# AC7842x register map
Vendor: AutoChips; Series: AC78; File version: 1.0
CPU: CM4 r0p1, little endian, MPU, FPU, VTOR, 4 interrupt priority bits
Registers are 32-bit, read-write, reset 0x0 unless marked. A register's access mark holds for its fields unless they carry their own. Offsets are from the block's base; [hi:lo] are bit positions; {n}, {i} and the like mark numbered series; 'fields as' and 'values as' point back to an identical list.

## SMU — Safety Management Uint
Base 0x40089000
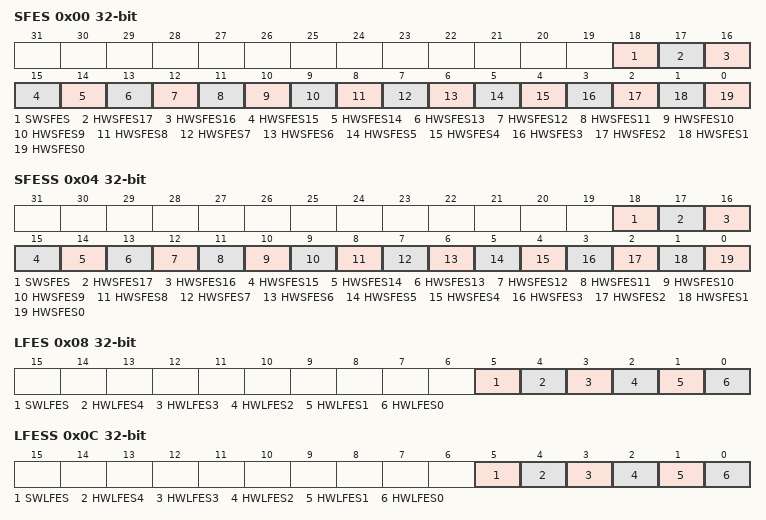
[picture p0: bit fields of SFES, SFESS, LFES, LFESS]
0x00 SFES — Single Point Fault Error Status Register
  [18] SWSFES — Software single fault error detected
  [17] HWSFES17 — FlexRAM ECC error detected
  [16] HWSFES16 — CPU lock up
  [15] HWSFES15 — Cache parity error
  [14] HWSFES14 — Low voltage detection of FLHLDO
  [13] HWSFES13 — Low voltage detection of DIGLDO
  [12] HWSFES12 — Low voltage detection of DVDD
  [11] HWSFES11 — WDG timeout
  [10] HWSFES10 — The number of trigger generated in a counting period is not equal to the set number detected
  [9] HWSFES9 — The number of trigger generated in a counting period is not equal to the set number detected
  [8] HWSFES8 — Flash ECC error detected
  [7] HWSFES7 — DMA parity error detected
  [6] HWSFES6 — End-to-end parity error detected
  [5] HWSFES5 — ECC 2 bits error detected
  [4] HWSFES4 — ECC 1 bit error detected
  [3] HWSFES3 — VHSI clock loss detected in digital module
  [2] HWSFES2 — HSE clock loss detected in digital module
  [1] HWSFES1 — PLL clock loss detected in digital module
  [0] HWSFES0 — PLL clock unlock detected in analog module
0x04 SFESS — Single Point Fault Error Status Shadow Register
  fields as SFES
0x08 LFES — Latent Fault Error Status Register
  [5] SWLFES — Software latent fault error
  [4] HWLFES4 — Memory build-in self-test error
  [3] HWLFES3 — Automatic build-in self-test error
  [2] HWLFES2 — Flash ECC error detected
  [1] HWLFES1 — ECC 1 bit error detected when EIM
  [0] HWLFES0 — ECC 2 bits error detected when EIM
0x0C LFESS — Latent Fault Error Status Shadow Register
  fields as LFES
0x10 LKSEQ0 — Lock Sequence for Single Point Fault Path
  [7:0] LKSEQ0
0x14 LKSEQ1 — Lock Sequence for Latent Fault Path
  [7:0] LKSEQ1
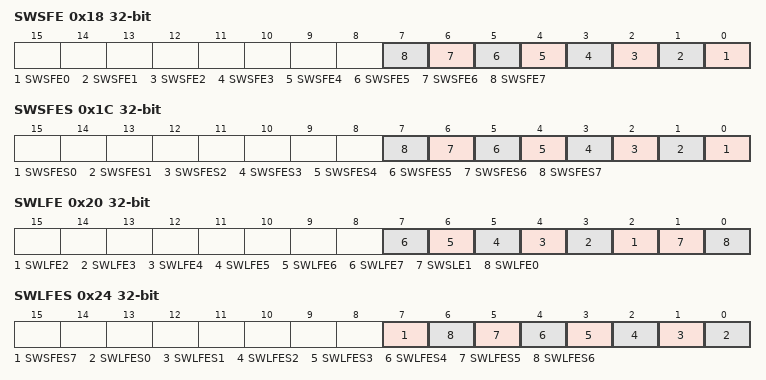
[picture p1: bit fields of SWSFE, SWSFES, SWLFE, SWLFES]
0x18 SWSFE — Software Single Point Fault Enable Register
  [n] SWSFE{n} (n=0..7) — Software Single Point Fault Enable {n}
0x1C SWSFES — Software Single Point Fault Enable Shadow Register
  [n] SWSFES{n} (n=0..7) — Software Single Point Fault Enable Shadow {n}
0x20 SWLFE — Software Latent Fault Enable Register
  [n] SWLFE{n} (n=2..7) — Software Latent Fault Enable {n}
  [1] SWSLE1 — Software Latent Fault Enable 1
  [0] SWLFE0 — Software Latent Fault Enable 0
0x24 SWLFES — Software Latent Fault Enable Shadow Register
  [7] SWSFES7 — Software Latent Fault Enable Shadow 7
  [n] SWLFES{n} (n=0..6) — Software Latent Fault Enable Shadow {n}
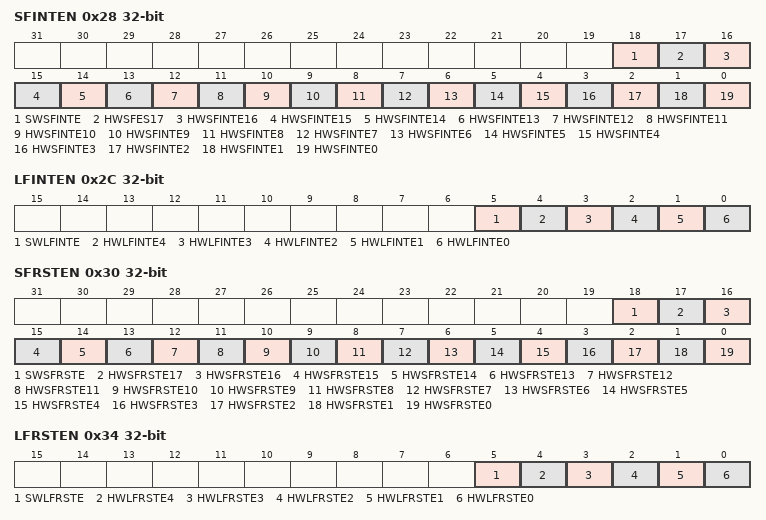
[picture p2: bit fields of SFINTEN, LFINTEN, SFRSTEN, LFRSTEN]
0x28 SFINTEN — Single Point Fault Interrupt Enable Register
  [18] SWSFINTE — Software single point interrupt enable
  [17] HWSFES17 — FlexRAM ECC error detected interrupt enable
  [16] HWSFINTE16 — CPU lock up interrupt enable
  [15] HWSFINTE15 — PFlash Cache ECC error interrupt enable
  [14] HWSFINTE14 — Low voltage detection of FLHLDO interrupt enable
  [13] HWSFINTE13 — Low voltage detection of DIGLDO interrupt enable
  [12] HWSFINTE12 — Low voltage detection of DVDD interrupt enable
  [11] HWSFINTE11 — WDG timeout interrupt enable
  [10] HWSFINTE10 — PDT0 error interrupt enable
  [9] HWSFINTE9 — PDT1 error interrupt enable
  [8] HWSFINTE8 — Flash ECC error interrupt enable
  [7] HWSFINTE7 — DMA ECC error interrupt enable
  [6] HWSFINTE6 — End-to-end ECC error interrupt enable
  [5] HWSFINTE5 — SRAM ECC 2 bits error interrupt enable
  [4] HWSFINTE4 — SRAM ECC 1 bit error interrupt enable
  [3] HWSFINTE3 — VHSI clock loss interrupt enable
  [2] HWSFINTE2 — HSE clock loss interrupt enable
  [1] HWSFINTE1 — PLL clock loss interrupt enable
  [0] HWSFINTE0 — PLL clock unlock interrupt enable
0x2C LFINTEN — Latent Fault Interrupt Enable Register
  [5] SWLFINTE — Software latent fault interrupt enable
  [4] HWLFINTE4 — Memory build-in self-test error interrupt enable
  [3] HWLFINTE3 — Automatic build-in self-test error interrupt enable
  [2] HWLFINTE2 — Flash ECC error interrupt enable
  [1] HWLFINTE1 — ECC 1 bit error(EIM) interrupt enable
  [0] HWLFINTE0 — ECC 2 bits error(EIM) interrupt enable
0x30 SFRSTEN — Single Point Fault Reset Enable Register
  [18] SWSFRSTE — Software single point reset enable
  [17] HWSFRSTE17 — FlexRAM ECC error reset enable
  [16] HWSFRSTE16 — CPU lock up reset enable
  [15] HWSFRSTE15 — Cache parity error reset enable
  [14] HWSFRSTE14 — Low voltage detection of FLHLDO reset enable
  [13] HWSFRSTE13 — Low voltage detection of DIGLDO reset enable
  [12] HWSFRSTE12 — Low voltage detection of DVDD reset enable
  [11] HWSFRSTE11 — WDG timeout reset enable
  [10] HWSFRSTE10 — PDT0 error reset enable
  [9] HWSFRSTE9 — PDT1 error reset enable
  [8] HWSFRSTE8 — Flash ECC error reset enable
  [7] HWSFRSTE7 — DMA parity error reset enable
  [6] HWSFRSTE6 — End-to-end parity error reset enable
  [5] HWSFRSTE5 — ECC 2 bits error reset enable
  [4] HWSFRSTE4 — ECC 1 bit error reset enable
  [3] HWSFRSTE3 — VHSI clock loss reset enable
  [2] HWSFRSTE2 — HSE clock loss reset enable
  [1] HWSFRSTE1 — PLL clock loss reset enable
  [0] HWSFRSTE0 — PLL clock unlock reset enable
0x34 LFRSTEN — Latent Fault Reset Request Enable Register
  [5] SWLFRSTE — Software latent fault reset enable
  [4] HWLFRSTE4 — Memory build-in self-test error reset enable
  [3] HWLFRSTE3 — Automatic build-in self-test error reset enable
  [2] HWLFRSTE2 — Flash ECC error reset enable
  [1] HWLFRSTE1 — ECC 1 bit error(EIM) reset enable
  [0] HWLFRSTE0 — ECC 2 bits error(EIM) reset enable
0x38 SRSTCNTVAL — System Reset Request Counter Threshold Register
  [3:0] SRSTCNTVAL — System Reset request counter threshold
0x3C SRSTCNT — System Reset Request Counter Register
  [3:0] SRSTCNT — System Reset request counter
0x40 SRSTCNTS — System Reset Request Counter Shadow Register
  [3:0] SRSTCNTS — System Reset request counter shadow
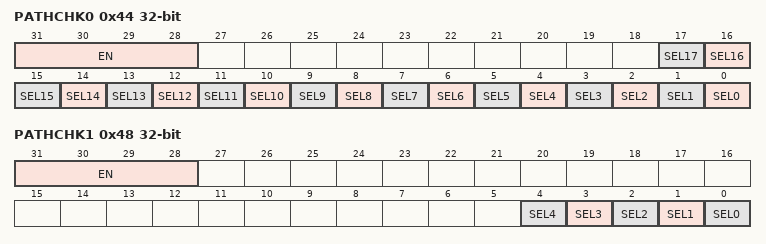
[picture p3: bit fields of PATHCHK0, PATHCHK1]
0x44 PATHCHK0 — Path Check for Single Point Fault Path Register
  [31:28] EN — Path check enable for path 0(Single Point Fault Path).
  [17] SEL17 — FlexRAM ECC error path trigger by software
  [16] SEL16 — CPU lock up path trigger by software
  [15] SEL15 — Cache parity error path trigger by software
  [14] SEL14 — Low voltage detection of FLHLDO path trigger by software
  [13] SEL13 — Low voltage detection of DIGLDO path trigger by software
  [12] SEL12 — Low voltage detection of DVDD path trigger by software
  [11] SEL11 — WDG timeout path trigger by software
  [10] SEL10 — PDT0 error path trigger by software
  [9] SEL9 — PDT1 error path trigger by software
  [8] SEL8 — Flash ECC error path trigger by software
  [7] SEL7 — DMA parity error path trigger by software
  [6] SEL6 — End-to-end parity error path trigger by software
  [5] SEL5 — ECC 2 bits error path trigger by software
  [4] SEL4 — ECC 1 bit error path trigger by software
  [3] SEL3 — VHSI clock loss path trigger by software
  [2] SEL2 — HSE clock loss path trigger by software
  [1] SEL1 — PLL clock loss path trigger by software
  [0] SEL0 — PLL clock unlock path trigger by software
0x48 PATHCHK1 — Path Check for Latent Fault Error Path Register
  [31:28] EN — Path Check enable for path 1(Latent Fault Path)
  [4] SEL4 — Memory build-in self-test error path trigger by software
  [3] SEL3 — Automatic build-in self-test error path trigger by software
  [2] SEL2 — Flash ECC error path trigger by software
  [1] SEL1 — ECC 1 bit error(EIM) path trigger by software
  [0] SEL0 — ECC 2 bits error(EIM) path trigger by software
